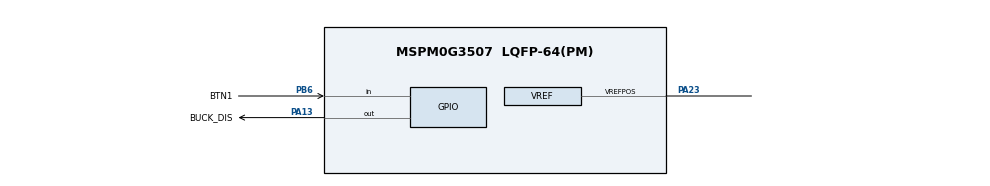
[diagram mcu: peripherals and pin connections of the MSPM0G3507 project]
/**
 * These arguments were used when this file was generated. They will be automatically applied on subsequent loads
 * via the GUI or CLI. Run CLI with '--help' for additional information on how to override these arguments.
 * @cliArgs --device "MSPM0G350X" --part "Default" --package "LQFP-64(PM)" --product "mspm0_sdk@2.09.00.01"
 * @v2CliArgs --device "MSPM0G3507" --package "LQFP-64(PM)" --product "mspm0_sdk@2.09.00.01"
 * @versions {"tool":"1.25.0+4268"}
 */

/**
 * Import the modules used in this configuration.
 */
const ADC12   = scripting.addModule("/ti/driverlib/ADC12", {}, false);
const ADC121  = ADC12.addInstance();
const ADC122  = ADC12.addInstance();
const Board   = scripting.addModule("/ti/driverlib/Board");
const GPIO    = scripting.addModule("/ti/driverlib/GPIO", {}, false);
const GPIO1   = GPIO.addInstance();
const GPIO2   = GPIO.addInstance();
const RTC     = scripting.addModule("/ti/driverlib/RTC");
const SYSCTL  = scripting.addModule("/ti/driverlib/SYSCTL");
const SYSTICK = scripting.addModule("/ti/driverlib/SYSTICK");
const UART    = scripting.addModule("/ti/driverlib/UART", {}, false);
const UART1   = UART.addInstance();
const VREF    = scripting.addModule("/ti/driverlib/VREF");

/**
 * Write custom configuration values to the imported modules.
 */
ADC121.$name                             = "ADC0";
ADC121.adcPin0Config.$name               = "ti_driverlib_gpio_GPIOPinGeneric0";
ADC121.adcPin0Config.hideOutputInversion = scripting.forceWrite(false);

ADC122.$name                             = "ADC1";
ADC122.adcPin0Config.$name               = "ti_driverlib_gpio_GPIOPinGeneric1";
ADC122.adcPin0Config.hideOutputInversion = scripting.forceWrite(false);

Board.configureUnused = true;

GPIO1.$name                                  = "EN";
GPIO1.associatedPins.create(11);
GPIO1.associatedPins[0].$name                = "BATTERY_ENABLE";
GPIO1.associatedPins[0].assignedPort         = "PORTB";
GPIO1.associatedPins[0].assignedPin          = "21";
GPIO1.associatedPins[1].$name                = "BUCK_DIS";
GPIO1.associatedPins[1].assignedPort         = "PORTA";
GPIO1.associatedPins[1].assignedPin          = "13";
GPIO1.associatedPins[1].pin.$assign          = "PA13";
GPIO1.associatedPins[2].$name                = "CHARGER_ENABLE";
GPIO1.associatedPins[2].assignedPort         = "PORTB";
GPIO1.associatedPins[2].assignedPortSegment  = "Upper";
GPIO1.associatedPins[2].assignedPin          = "27";
GPIO1.associatedPins[3].$name                = "OUTPUT_ENABLE";
GPIO1.associatedPins[3].assignedPort         = "PORTB";
GPIO1.associatedPins[3].assignedPortSegment  = "Upper";
GPIO1.associatedPins[3].assignedPin          = "26";
GPIO1.associatedPins[4].$name                = "VBATM_EN";
GPIO1.associatedPins[4].assignedPort         = "PORTB";
GPIO1.associatedPins[4].assignedPin          = "22";
GPIO1.associatedPins[5].$name                = "USB_EN";
GPIO1.associatedPins[5].assignedPort         = "PORTA";
GPIO1.associatedPins[5].assignedPortSegment  = "Lower";
GPIO1.associatedPins[5].assignedPin          = "5";
GPIO1.associatedPins[6].$name                = "LED_EN";
GPIO1.associatedPins[6].assignedPort         = "PORTB";
GPIO1.associatedPins[6].assignedPin          = "13";
GPIO1.associatedPins[7].$name                = "LED_DIS";
GPIO1.associatedPins[7].assignedPort         = "PORTB";
GPIO1.associatedPins[7].assignedPin          = "5";
GPIO1.associatedPins[8].$name                = "USB_LD1_EN";
GPIO1.associatedPins[8].assignedPort         = "PORTB";
GPIO1.associatedPins[8].assignedPin          = "1";
GPIO1.associatedPins[9].$name                = "USB_LD2_EN";
GPIO1.associatedPins[9].assignedPort         = "PORTB";
GPIO1.associatedPins[9].assignedPin          = "2";
GPIO1.associatedPins[10].$name               = "CRT_SNS_EN";
GPIO1.associatedPins[10].assignedPort        = "PORTB";
GPIO1.associatedPins[10].assignedPortSegment = "Upper";
GPIO1.associatedPins[10].assignedPin         = "16";

GPIO2.$name                         = "BTNS";
GPIO2.port                          = "PORTB";
GPIO2.associatedPins.create(2);
GPIO2.associatedPins[0].$name       = "BTN1";
GPIO2.associatedPins[0].direction   = "INPUT";
GPIO2.associatedPins[0].assignedPin = "6";
GPIO2.associatedPins[0].pin.$assign = "PB6";
GPIO2.associatedPins[1].$name       = "BTN2";
GPIO2.associatedPins[1].direction   = "INPUT";
GPIO2.associatedPins[1].assignedPin = "7";


SYSCTL.forceDefaultClkConfig  = true;
SYSCTL.powerPolicy            = "STANDBY0";
SYSCTL.flashInterruptPriority = "2";
SYSCTL.clockTreeEn            = true;

SYSTICK.periodEnable    = true;
SYSTICK.interruptEnable = true;
SYSTICK.systickEnable   = true;
SYSTICK.period          = 4000;

UART1.$name             = "UART_0";
UART1.targetBaudRate    = 115200;
UART1.txPinConfig.$name = "ti_driverlib_gpio_GPIOPinGeneric4";
UART1.rxPinConfig.$name = "ti_driverlib_gpio_GPIOPinGeneric5";

VREF.basicIntVolt                  = "DL_VREF_BUFCONFIG_OUTPUT_2_5V";
VREF.checkVREFReady                = true;
VREF.basicVrefPins                 = "VREF+-";
VREF.vrefPosPinConfig.$name        = "ti_driverlib_gpio_GPIOPinGeneric2";
VREF.peripheral.vrefPosPin.$assign = "PA23";
VREF.vrefNegPinConfig.$name        = "ti_driverlib_gpio_GPIOPinGeneric3";

/**
 * Pinmux solution for unlocked pins/peripherals. This ensures that minor changes to the automatic solver in a future
 * version of the tool will not impact the pinmux you originally saw.  These lines can be completely deleted in order to
 * re-solve from scratch.
 */
ADC121.peripheral.$suggestSolution            = "ADC1";
ADC121.peripheral.adcPin0.$suggestSolution    = "PA15";
ADC122.peripheral.$suggestSolution            = "ADC0";
ADC122.peripheral.adcPin0.$suggestSolution    = "PA27";
Board.peripheral.$suggestSolution             = "DEBUGSS";
Board.peripheral.swclkPin.$suggestSolution    = "PA20";
Board.peripheral.swdioPin.$suggestSolution    = "PA19";
GPIO1.associatedPins[0].pin.$suggestSolution  = "PB21";
GPIO1.associatedPins[2].pin.$suggestSolution  = "PB27";
GPIO1.associatedPins[3].pin.$suggestSolution  = "PB26";
GPIO1.associatedPins[4].pin.$suggestSolution  = "PB22";
GPIO1.associatedPins[5].pin.$suggestSolution  = "PA5";
GPIO1.associatedPins[6].pin.$suggestSolution  = "PB13";
GPIO1.associatedPins[7].pin.$suggestSolution  = "PB5";
GPIO1.associatedPins[8].pin.$suggestSolution  = "PB1";
GPIO1.associatedPins[9].pin.$suggestSolution  = "PB2";
GPIO1.associatedPins[10].pin.$suggestSolution = "PB16";
GPIO2.associatedPins[1].pin.$suggestSolution  = "PB7";
RTC.peripheral.$suggestSolution               = "RTC";
UART1.peripheral.$suggestSolution             = "UART0";
UART1.peripheral.rxPin.$suggestSolution       = "PA1";
UART1.peripheral.txPin.$suggestSolution       = "PA0";
VREF.peripheral.$suggestSolution              = "VREF";
VREF.peripheral.vrefNegPin.$suggestSolution   = "PA21";
